# CMPSSA_CMPSSA_50200000h register map
Vendor: Texas Instruments
Peripheral module from a debugger description file (folder AM261x).
Registers are 16-bit, read-write, reset 0x0 unless marked. A register's access mark holds for its fields unless they carry their own. Offsets are as the file gives them; lines under a group give offsets from that group; [hi:lo] are bit positions; {n}, {i} and the like mark numbered series; 'fields as' and 'values as' point back to an identical list; <NAME> marks a mode.

## CMPSSA
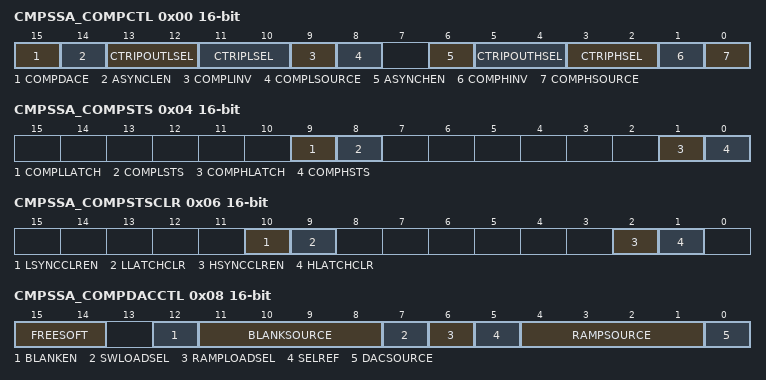
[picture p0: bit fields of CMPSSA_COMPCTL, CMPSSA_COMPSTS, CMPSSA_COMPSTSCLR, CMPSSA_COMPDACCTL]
0x00 CMPSSA_COMPCTL — CMPSS Comparator Control Register.
  [15] COMPDACE — Comparator/DAC enable. 0 Comparator/DAC disabled 1 Comparator/DAC enabled
  [14] ASYNCLEN — Low comparator asynchronous path enable. Allows asynchronous comparator output to feed into OR gate with latched digital filter signal when CTRIPLSEL=3 or CTRIPOUTLSEL=3. 0 Asynchronous comparator output does not feed into OR gate with latched digital filter output 1 Asynchronous comparator output feeds into OR gate with latched digital filter output
  [13:12] CTRIPOUTLSEL — Low comparator CTRIPOUTL source select. 0 Asynchronous comparator output drives CTRIPOUTL 1 Synchronous comparator output drives CTRIPOUTL 2 Output of digital filter drives CTRIPOUTL 3 Latched output of digital filter drives CTRIPOUTL
  [11:10] CTRIPLSEL — Low comparator CTRIPL source select. 0 Asynchronous comparator output drives CTRIPL 1 Synchronous comparator output drives CTRIPL 2 Output of digital filter drives CTRIPL 3 Latched output of digital filter drives CTRIPL
  [9] COMPLINV — Low comparator output invert. 0 Output of comparator is not inverted 1 Output of comparator is inverted
  [8] COMPLSOURCE — CompL Pos Mux Select0 positive mux selects INL_3p3v voltage [default]1 postive mux selects INH_3p3v
  [6] ASYNCHEN — High comparator asynchronous path enable. Allows asynchronous comparator output to feed into OR gate with latched digital filter signal when CTRIPHSEL=3 or CTRIPOUTHSEL=3. 0 Asynchronous comparator output does not feed into OR gate with latched digital filter output 1 Asynchronous comparator output feeds into OR gate with latched digital filter output
  [5:4] CTRIPOUTHSEL — High comparator CTRIPOUTH source select. 0 Asynchronous comparator output drives CTRIPOUTH 1 Synchronous comparator output drives CTRIPOUTH 2 Output of digital filter drives CTRIPOUTH 3 Latched output of digital filter drives CTRIPOUTH
  [3:2] CTRIPHSEL — High comparator CTRIPH source select. 0 Asynchronous comparator output drives CTRIPH 1 Synchronous comparator output drives CTRIPH 2 Output of digital filter drives CTRIPH 3 Latched output of digital filter drives CTRIPH
  [1] COMPHINV — High comparator output invert. 0 Output of comparator is not inverted 1 Output of comparator is inverted
  [0] COMPHSOURCE — CompH neg Mux slect0 negative mux selects DAC voltage [default]1 negative mux selects INL_3p3v
0x04 CMPSSA_COMPSTS ro — CMPSS Comparator Status Register.
  [9] COMPLLATCH — Latched value of low comparator digital filter output
  [8] COMPLSTS — Low comparator digital filter output
  [1] COMPHLATCH — Latched value of high comparator digital filter output
  [0] COMPHSTS — High comparator digital filter output
0x06 CMPSSA_COMPSTSCLR access not given — CMPSS Comparator Status Clear Register.
  [10] LSYNCCLREN rw — Low comparator latch EPWMSYNCPER clear. Enable EPWMSYNCPER reset of low comparator digital filter output latch COMPSTS[COMPLLATCH]. 0 EPWMSYNCPER will not reset latch 1 EPWMSYNCPER will reset latch
  [9] LLATCHCLR — Low comparator latch software clear. Perform software reset of low comparator digital filter output latch COMPSTS[COMPLLATCH]. Reads always return 0. 0 No effect 1 Generate a single pulse of latch reset signal for COMPSTS[COMPLLATCH] (access R/W1TS)
  [2] HSYNCCLREN rw — High comparator latch EPWMSYNCPER clear. Enable EPWMSYNCPER reset of high comparator digital filter output latch COMPSTS[COMPHLATCH]. 0 EPWMSYNCPER will not reset latch 1 EPWMSYNCPER will reset latch
  [1] HLATCHCLR — High comparator latch software clear. Perform software reset of high comparator digital filter output latch COMPSTS[COMPHLATCH]. Reads always return 0. 0 No effect 1 Generate a single pulse of latch reset signal for COMPSTS[COMPHLATCH] (access R/W1TS)
0x08 CMPSSA_COMPDACCTL — CMPSS DAC Control Register.
  [15:14] FREESOFT — Free-run or software-run emulation behavior. Behavior of the ramp generator during emulation suspend. 00b Ramp generator stops immediately during emulation suspend 01b Ramp generator completes current ramp and stops at next EPWMSYNCPER during emulation suspend 1Xb Ramp generator runs freely
  [12] BLANKEN — EPWMBLANK enable. This bit enables the EPWMBLANK signal. 0 EPWMBLANK signal is disabled. 1 EPWMBLANK signal is enabled.
  [11:8] BLANKSOURCE — EPWMBLANK source select. This bit field determines which EPWMnBLANK is passed on as the EPWMBLANK signal. Where n represents the maximum number of EPWMBLANK signals available on the device: 0 EPWM0BLANK 1 EPWM1BLANK 2 EPWM2BLANK ... n-1 EPWM(n-1)BLANK
  [7] SWLOADSEL — Software load select. Determines whether DACxVALA is updated from DACxVALS on SYSCLK or EPWMSYNCPER. 0 DACxVALA is updated from DACxVALS on SYSCLK 1 DACxVALA is updated from DACxVALS on EPWMSYNCPER
  [6] RAMPLOADSEL — Ramp load select. Determines whether RAMPSTS is updated from RAMPMAXREFA or RAMPMAXREFS when COMPSTS[COMPHSTS] is triggered. 0 RAMPSTS is loaded from RAMPMAXREFA 1 RAMPSTS is loaded from RAMPMAXREFS
  [5] SELREF — CMPSS reference select0 vref_1p8v as reference voltage [default]1 vdd_1p8v as reference voltage
  [4:1] RAMPSOURCE — EPWMSYNCPER source select. Determines which EPWMnSYNCPER signal is used within the CMPSS module. Where n represents the maximum number of EPWMSYNCPER signals available on the device: 0 EPWM1SYNCPER 1 EPWM2SYNCPER 2 EPWM3SYNCPER ... n-1 EPWMnSYNCPER
  [0] DACSOURCE — DAC source select. Determines whether DACHVALA is updated from DACHVALS or from the ramp generator. 0 DACHVALA is updated from DACHVALS 1 DACHVALA is updated from the ramp generator
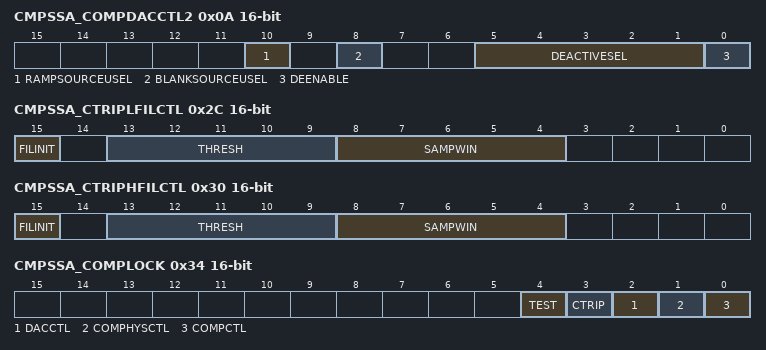
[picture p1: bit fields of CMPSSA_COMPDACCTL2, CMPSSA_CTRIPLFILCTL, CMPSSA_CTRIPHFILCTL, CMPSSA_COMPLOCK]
0x0A CMPSSA_COMPDACCTL2 — CMPSS DAC Control Register 2
  [10] RAMPSOURCEUSEL — 0: Selects EPWM0 to 15 as RAMP source 1:Selects EPWM16 to 31 as RAMP source
  [8] BLANKSOURCEUSEL — 0: Selects EPWM0 to 15 as blank source 1:Selects EPWM16 to 31 as blank source
  [5:1] DEACTIVESEL — DEACTIVE source select: 0 : EPWM0.DEACTIVE 1 : EPWM1.DEACTIVE 2 : EPWM2.DEACTIVE 3 : EPWM3.DEACTIVE . . 31 : EPWM31.DEACTIVE
  [0] DEENABLE — DE mode enable. 0 DE mode features disabled. 1 DE mode features enabled.
0x0C CMPSSA_DACHVALS — CMPSS High DAC Value Shadow Register.
  [11:0] DACVAL — High DAC shadow value. When COMPDACCTL[DACSOURCE]=0, the value of DACHVALS is loaded into DACHVALA on the trigger signal selected by COMPDACCTL[SWLOADSEL].
0x0E CMPSSA_DACHVALA ro — CMPSS High DAC Value Active Register.
  [11:0] DACVAL — High DAC active value. Value that is actively driven by the high DAC.
0x10 CMPSSA_RAMPMAXREFA ro — CMPSS Ramp Max Reference Active Register.
  [15:0] RAMPMAXREF — Ramp maximum reference active value. Latched value to be loaded into ramp generator RAMPSTS.
0x14 CMPSSA_RAMPMAXREFS — CMPSS Ramp Max Reference Shadow Register.
  [15:0] RAMPMAXREF — Ramp maximum reference shadow. Unlatched value to be loaded into ramp generator RAMPSTS.
0x18 CMPSSA_RAMPDECVALA ro — CMPSS Ramp Decrement Value Active Register.
  [15:0] RAMPDECVAL — Ramp decrement value active. Latched value that will be subtracted from RAMPSTS.
0x1C CMPSSA_RAMPDECVALS — CMPSS Ramp Decrement Value Shadow Register.
  [15:0] RAMPDECVAL — Ramp decrement value shadow. Unlatched value to be loaded into RAMPDECVALA.
0x20 CMPSSA_RAMPSTS ro — CMPSS Ramp Status Register.
  [15:0] RAMPVALUE — Ramp value. Present value of ramp generator.
0x24 CMPSSA_DACLVALS — CMPSS Low DAC Value Shadow Register.
  [11:0] DACVAL — Low DAC shadow value. value to be loaded into DACLVALA on the trigger signal selected by COMPDACCTL[SWLOADSEL].
0x26 CMPSSA_DACLVALA ro — CMPSS Low DAC Value Active Register.
  [11:0] DACVAL — Low DAC active value. Value that is actively driven by the low DAC.
0x28 CMPSSA_RAMPDLYA ro — CMPSS Ramp Delay Active Register.
  [12:0] DELAY — Ramp delay active value. Latched value of the number of cycles to delay the start of the ramp generator decrementer after a EPWMSYNCPER is received.
0x2A CMPSSA_RAMPDLYS — CMPSS Ramp Delay Shadow Register.
  [12:0] DELAY — Ramp delay shadow value. Unlatched value to be loaded into RAMPDLYA.
0x2C CMPSSA_CTRIPLFILCTL access not given — CTRIPL Filter Control Register.
  [15] FILINIT — Low filter initialization. 0 No effect 1 Initialize all samples to the filter input value (access R/W1TS)
  [13:9] THRESH rw — Low filter majority voting threshold. At least THRESH samples of the opposite state must appear within the sample window in order for the output to change state. Threshold used is THRESH+1.
  [8:4] SAMPWIN rw — Low filter sample window size. Number of samples to monitor is SAMPWIN+1.
0x2E CMPSSA_CTRIPLFILCLKCTL — CTRIPL Filter Clock Control Register.
  [15:0] CLKPRESCALE — Low filter sample clock prescale. Number of system clocks between samples is CLKPRESCALE+1.
0x30 CMPSSA_CTRIPHFILCTL access not given — CTRIPH Filter Control Register.
  [15] FILINIT — High filter initialization. 0 No effect 1 Initialize all samples to the filter input value (access R/W1TS)
  [13:9] THRESH rw — High filter majority voting threshold. At least THRESH samples of the opposite state must appear within the sample window in order for the output to change state. Threshold used is THRESH+1.
  [8:4] SAMPWIN rw — High filter sample window size. Number of samples to monitor is SAMPWIN+1.
0x32 CMPSSA_CTRIPHFILCLKCTL — CTRIPH Filter Clock Control Register.
  [15:0] CLKPRESCALE — High filter sample clock prescale. Number of system clocks between samples is CLKPRESCALE+1.
0x34 CMPSSA_COMPLOCK access not given — CMPSS Lock Register.
  [4] TEST — TEST Lock. This bit, when set, will prevent any further writes to the any undocumented registers that may effect the performance/behavior of this block. Once set this bit can only be cleared by a reset. (access R/W1TS)
  [3] CTRIP — Lock write-access to the CTRIPxFILTCTL and CTRIPxFILCLKCTL registers. 0 CTRIPxFILCTL and CTRIPxFILCLKCTL registers are not locked. Write 0 to this bit has no effect. 1 CTRIPxFILCTL and CTRIPxFILCLKCTL registers are locked. Only a system reset can clear this bit. (access R/W1TS)
  [2] DACCTL — Lock write-access to the DACCTL register. 0 DACCTL register is not locked. Write 0 to this bit has no effect. 1 DACCTL register is locked. Only a system reset can clear this bit. (access R/W1TS)
  [1] COMPHYSCTL — Lock write-access to the COMPHYSCTL register. 0 COMPHYSCTL register is not locked. Write 0 to this bit has no effect. 1 COMPHYSCTL register is locked. Only a system reset can clear this bit. (access R/W1TS)
  [0] COMPCTL — Lock write-access to the COMPCTL register. 0 COMPCTL register is not locked. Write 0 to this bit has no effect. 1 COMPCTL register is locked. Only a system reset can clear this bit. (access R/W1TS)
0x38 CMPSSA_DACHVALS2 — CMPSS High DAC Value Shadow Register 2
  [11:0] DACVAL — High DAC shadow register2 value. When COMPDACCTL[DACSOURCE]=0, the value of DACHVALS2 is loaded into DACHVALA when DE mode is enabled and selected DEACTIVE input is asserted.
0x3A CMPSSA_DACLVALS2 — CMPSS Low DAC Value Shadow Register 2
  [11:0] DACVAL — Low DAC shadow register2 value. Value of DACHVALS2 is loaded into DACHVALA when DE mode is enabled and selected DEACTIVE input is asserted.
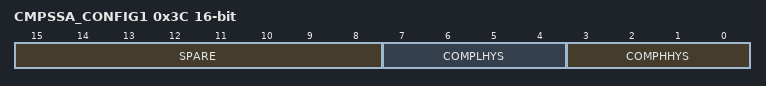
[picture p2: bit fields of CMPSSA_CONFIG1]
0x3C CMPSSA_CONFIG1 — CMPSS Config1 Register.
  [15:8] SPARE
  [7:4] COMPLHYS — CompL HysteresisCOMPLHYS[3] : reservedCOMPLHYS[2] : Controls which comparator output value hysteresis is applied to. 1'b0 : Hysteresis is applied when the comparator output is 1'b11'b1 : Hysteresis is applied when the comparator output is 1'b0COMPLHYS[1:0] = hysteresis value2'b00 : 0 LSB2'b01 : 17.5 LSB2'b10 : 35 LSB2'b11 : 52.5 LSB
  [3:0] COMPHHYS — CompH HysteresisCOMPHHYS[3] : reservedCOMPHHYS[2] : Controls which comparator output value hysteresis is applied to. 1'b0 : Hysteresis is applied when the comparator output is 1'b11'b1 : Hysteresis is applied when the comparator output is 1'b0COMPHHYS[1:0] = hysteresis value2'b00 : 0 LSB2'b01 : 17.5 LSB2'b10 : 35 LSB2'b11 : 52.5 LSB
